# rpi3b register map
Vendor: Raspberr Pi Foundation; Series: raspberry pi; File version: 0.1
Single Board Computer With An ARM A-53 Quad Core CPU in a BCM2837 SOC
CPU: CA53 r3p0, little endian, MPU, FPU, I-cache, D-cache, 0 interrupt priority bits
Registers are 32-bit, access not given, no defined reset value unless marked. A register's access mark holds for its fields unless they carry their own. Offsets are from the block's base; lines under a group give offsets from that group; [hi:lo] are bit positions; {n}, {i} and the like mark numbered series; 'fields as' and 'values as' point back to an identical list; <NAME> marks a mode.

## Memory map
? Auxillaries size 0x68 — The Device has three Auxiliary peripherals: One mini UART and two SPI masters. These three peripheral are grouped together as they share the same area in the peripheral register map and they share a common interrupt. Also all three are controlled by the auxiliary enable register.
? Timers size 0x1C — A free running, 64 bit timer and 2 (neé 4) match registers.
? InterruptController size 0x28 — BCM Interrupt controller (GIC).
? Mailbox size 0x24 — Videocore mailbox interface. inputs must be 16 byte aligned!
? ArmTimer size 0x24 — This is the timer that is on the arm chip. This is *not* the system timer peripheral. The arm-side timer is document in chapter 14 of the BCM2835 manual, whereas the system timer is documented in chapter 12. The qemu emulator does not have the match registers for the system timer. The arm-side timer requires care to use on real hardware, as it is tied to the system clock, whose speed can vary because of low-power modes. You need to either check the clock speed or configure it in your config.txt to have a stable value. This description has been updated to reflect the errors documented in the errata on pages 197 and 198.

## Timers — A free running, 64 bit timer and 2 (neé 4) match registers.
Base ?
0x00 ControlStatus — Timer Control and Status (Acknowledge Interrupts)
0x04 Lower32 — Lower 32 bits of the 64 bit timer
0x08 Upper32 — Upper 32 bits of the 64 bit timer
0x10 Match1 — Timer Match Register 1
0x18 Match3 — Timer Match Register 3

## InterruptController — BCM Interrupt controller (GIC).
Base ?
0x00 BasicPending — Basic Interrupt Pending
  [0] ARMTimer
0x04 Pending1 — Interrupt Group 1 Pending
0x08 Pending2 — Interrupt Group 2 Pending
0x0C FIQControl — Controls "fast" interrupts
0x10 EnableIRQs1 rw — Enable Group 1 Interrupts
  [29] AuxInterrupt
0x14 EnableIRQs2 — Enable Group 2 Interrupts
0x18 EnableBasic — Enable Basic Interrupts
  [0] ARMTimer
0x1C DisableIRQs1 rw — Disable Group 1 Interrupts
  [29] AuxInterrupt
0x20 DisableIRQs2 — Disable Group 2 Interrupts
0x24 DisableBasic — Disable Basic Interrupts
  [0] ARMTimer

## Mailbox — Videocore mailbox interface. inputs must be 16 byte aligned!
Base ?
0x00 Read
0x10 Poll
0x14 Sender
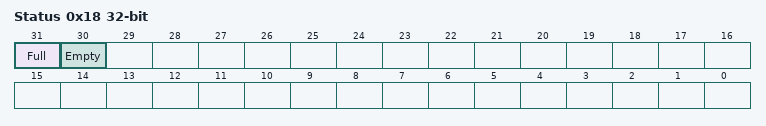
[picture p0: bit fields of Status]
0x18 Status ro
  [31] Full — Is the mailbox already full?
  [30] Empty — Is the mailbox empty?
0x1C Config
0x20 Write

## Licence text in the file
MIT License Copyright (c) 2020 Ian Smith Permission is hereby granted, free of charge, to any person obtaining a copy of this software and associated documentation files (the "Software"), to deal in the Software without restriction, including without limitation the rights to use, copy, modify, merge, publish, distribute, sublicense, and/or sell copies of the Software, and to permit persons to whom the Software is furnished to do so, subject to the following conditions: The above copyright notice and this permission notice shall be included in all copies or substantial portions of the Software. THE SOFTWARE IS PROVIDED "AS IS", WITHOUT WARRANTY OF ANY KIND, EXPRESS OR IMPLIED, INCLUDING BUT NOT LIMITED TO THE WARRANTIES OF MERCHANTABILITY, FITNESS FOR A PARTICULAR PURPOSE AND NONINFRINGEMENT. IN NO EVENT SHALL THE AUTHORS OR COPYRIGHT HOLDERS BE LIABLE FOR ANY CLAIM, DAMAGES OR OTHER LIABILITY, WHETHER IN AN ACTION OF CONTRACT, TORT OR OTHERWISE, ARISING FROM, OUT OF OR IN CONNECTION WITH THE SOFTWARE OR THE USE OR OTHER DEALINGS IN THE SOFTWARE.
